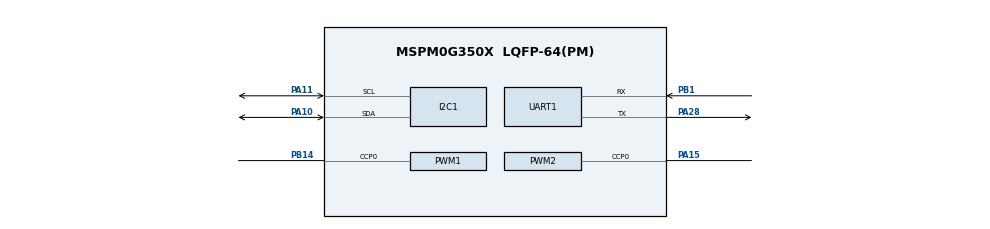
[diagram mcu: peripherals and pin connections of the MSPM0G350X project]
/**
 * @cliArgs --device "MSPM0G350X" --part "Default" --package "LQFP-64(PM)" --product "mspm0_sdk@2.10.00.04"
 * @versions {"tool":"1.26.2+4477"}
 */

/**
 * Import the modules used in this configuration.
 */
const GPIO   = scripting.addModule("/ti/driverlib/GPIO", {}, false);
const GPIO1  = GPIO.addInstance();
const GPIO2  = GPIO.addInstance();
const I2C    = scripting.addModule("/ti/driverlib/I2C", {}, false);
const I2C1   = I2C.addInstance();
const PWM    = scripting.addModule("/ti/driverlib/PWM", {}, false);
const PWM1   = PWM.addInstance();
const PWM2   = PWM.addInstance();
const SYSCTL = scripting.addModule("/ti/driverlib/SYSCTL");
const UART   = scripting.addModule("/ti/driverlib/UART", {}, false);
const UART1  = UART.addInstance();

/**
 * Write custom configuration values to the imported modules.
 */
GPIO1.$name                   = "STEP_MOTOR_A";
GPIO1.associatedPins.create(2);
GPIO1.associatedPins[0].$name = "DIR1";
GPIO1.associatedPins[1].$name = "EN1";

const Board = scripting.addModule("/ti/driverlib/Board", {}, false);

GPIO2.$name                   = "STEP_MOTOR_B";
GPIO2.associatedPins.create(2);
GPIO2.associatedPins[0].$name = "DIR2";
GPIO2.associatedPins[1].$name = "EN2";

I2C1.$name                     = "I2C_0";
I2C1.profile                   = "CONFIG_PROFILE_3";
I2C1.peripheral.sdaPin.$assign = "PA10";
I2C1.peripheral.sclPin.$assign = "PA11";
I2C1.sdaPinConfig.$name        = "ti_driverlib_gpio_GPIOPinGeneric2";
I2C1.sclPinConfig.$name        = "ti_driverlib_gpio_GPIOPinGeneric3";

PWM1.$name                      = "PWM_0";
PWM1.ccIndex                    = [0];
PWM1.PWM_CHANNEL_0.$name        = "ti_driverlib_pwm_PWMTimerCC0";
PWM1.ccp0PinConfig.$name        = "ti_driverlib_gpio_GPIOPinGeneric0";
PWM1.peripheral.ccp0Pin.$assign = "PB14";

PWM2.$name                      = "PWM_1";
PWM2.ccIndex                    = [0];
PWM2.PWM_CHANNEL_0.$name        = "ti_driverlib_pwm_PWMTimerCC1";
PWM2.ccp0PinConfig.$name        = "ti_driverlib_gpio_GPIOPinGeneric1";
PWM2.peripheral.ccp0Pin.$assign = "PA15";

SYSCTL.forceDefaultClkConfig = true;
SYSCTL.clockTreeEn           = true;

UART1.$name                    = "UART_0";
UART1.targetBaudRate           = 115200;
UART1.profile                  = "CONFIG_PROFILE_1";
UART1.peripheral.$assign       = "UART0";
UART1.peripheral.rxPin.$assign = "PB1";
UART1.peripheral.txPin.$assign = "PA28";
UART1.txPinConfig.$name        = "ti_driverlib_gpio_GPIOPinGeneric4";
UART1.rxPinConfig.$name        = "ti_driverlib_gpio_GPIOPinGeneric5";

/**
 * Pinmux solution for unlocked pins/peripherals. This ensures that minor changes to the automatic solver in a future
 * version of the tool will not impact the pinmux you originally saw.  These lines can be completely deleted in order to
 * re-solve from scratch.
 */
GPIO1.associatedPins[0].pin.$suggestSolution = "PB13";
GPIO1.associatedPins[1].pin.$suggestSolution = "PB15";
Board.peripheral.$suggestSolution            = "DEBUGSS";
Board.peripheral.swclkPin.$suggestSolution   = "PA20";
Board.peripheral.swdioPin.$suggestSolution   = "PA19";
GPIO2.associatedPins[0].pin.$suggestSolution = "PB16";
GPIO2.associatedPins[1].pin.$suggestSolution = "PA12";
I2C1.peripheral.$suggestSolution             = "I2C0";
PWM1.peripheral.$suggestSolution             = "TIMA0";
PWM2.peripheral.$suggestSolution             = "TIMA1";
